# sample register map
Vendor: nodamushi; Series: nodamushi test; File version: 1.0
Sample SVD for test
CPU: CM4 r1p0, little endian, MPU, no FPU, 3 interrupt priority bits
Registers are 32-bit, read-write, reset 0x0 unless marked. A register's access mark holds for its fields unless they carry their own. Offsets are from the block's base; lines under a group give offsets from that group; [hi:lo] are bit positions; {n}, {i} and the like mark numbered series; 'fields as' and 'values as' point back to an identical list; <NAME> marks a mode.

## Memory map
0x40000000 A size 0x100

## A
Base 0x40000000
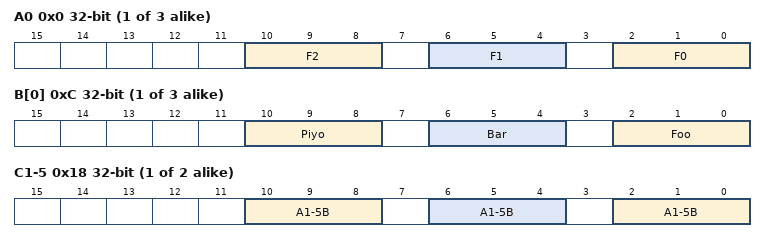
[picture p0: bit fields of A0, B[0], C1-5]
{0x0+4i} A{i} (i=0..2)
  [4n+2:4n] F{n} (n=0..2)
{0xC+4i} B[{i}] (i=0..2)
  [2:0] {x} (x=Foo,Bar,Piyo; step 4)
0x18 C{x} (x=1-5,10-15; step 0x4)
  [2:0] A{x}B (x=Foo,Bar,Piyo; step 4)
